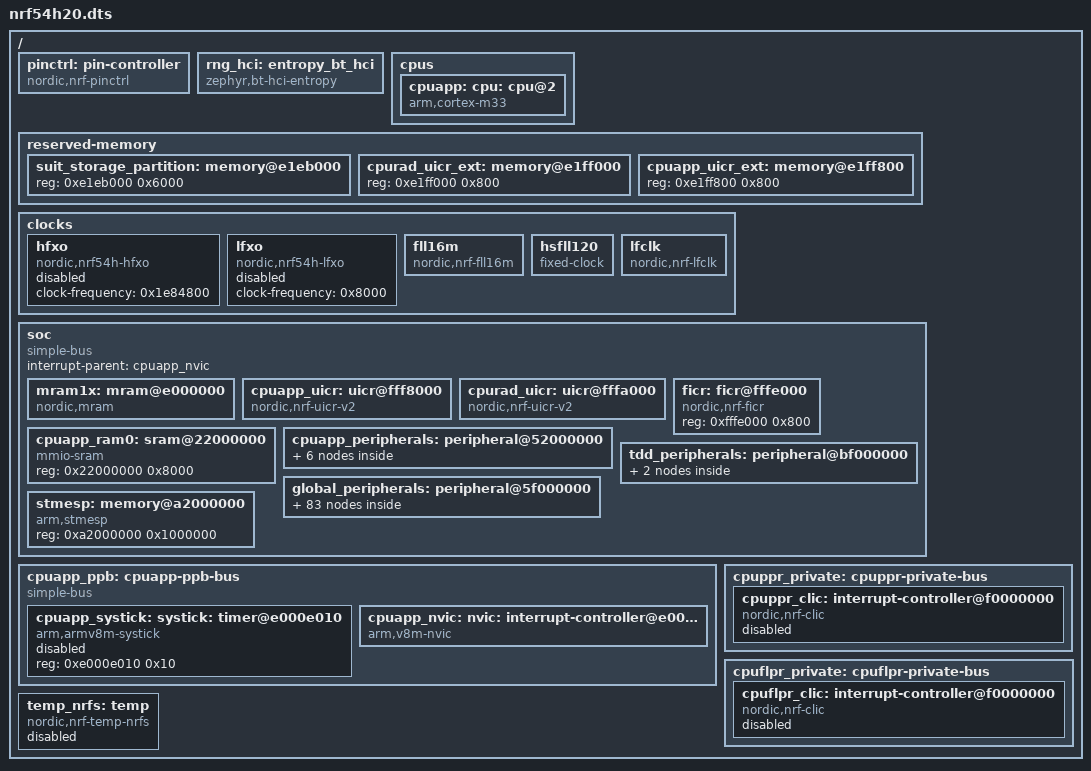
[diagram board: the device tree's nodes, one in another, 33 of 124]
/dts-v1/;

/ {
	#address-cells = < 0x1 >;
	#size-cells = < 0x1 >;
	pinctrl: pin-controller {
		compatible = "nordic,nrf-pinctrl";
	};
	rng_hci: entropy_bt_hci {
		compatible = "zephyr,bt-hci-entropy";
		status = "okay";
	};
	cpus {
		#address-cells = < 0x1 >;
		#size-cells = < 0x0 >;
		cpuapp: cpu: cpu@2 {
			compatible = "arm,cortex-m33";
			reg = < 0x2 >;
			device_type = "cpu";
			clocks = < &cpuapp_hsfll >;
			clock-frequency = < 0x1312d000 >;
		};
	};
	reserved-memory {
		#address-cells = < 0x1 >;
		#size-cells = < 0x1 >;
		suit_storage_partition: memory@e1eb000 {
			reg = < 0xe1eb000 0x6000 >;
		};
		cpurad_uicr_ext: memory@e1ff000 {
			reg = < 0xe1ff000 0x800 >;
			phandle = < 0x7 >;
		};
		cpuapp_uicr_ext: memory@e1ff800 {
			reg = < 0xe1ff800 0x800 >;
			phandle = < 0x6 >;
		};
	};
	clocks {
		hfxo: hfxo {
			compatible = "nordic,nrf54h-hfxo";
			status = "disabled";
			#clock-cells = < 0x0 >;
			clock-frequency = < 0x1e84800 >;
			phandle = < 0x2 >;
		};
		lfxo: lfxo {
			compatible = "nordic,nrf54h-lfxo";
			status = "disabled";
			#clock-cells = < 0x0 >;
			clock-frequency = < 0x8000 >;
			phandle = < 0x3 >;
		};
		fll16m: fll16m {
			compatible = "nordic,nrf-fll16m";
			#clock-cells = < 0x0 >;
			clock-frequency = < 0xf42400 >;
			open-loop-accuracy-ppm = < 0x4e20 >;
			closed-loop-base-accuracy-ppm = < 0x1388 >;
			clocks = < &hfxo >, < &lfxo >;
			clock-names = "hfxo", "lfxo";
			phandle = < 0x4 >;
		};
		hsfll120: hsfll120 {
			compatible = "fixed-clock";
			clocks = < &fll16m >;
			#clock-cells = < 0x0 >;
			clock-frequency = < 0x1312d000 >;
			phandle = < 0xb >;
		};
		lfclk: lfclk {
			compatible = "nordic,nrf-lfclk";
			#clock-cells = < 0x0 >;
			clock-frequency = < 0x8000 >;
			status = "okay";
			lfrc-accuracy-ppm = < 0x1f4 >;
			lflprc-accuracy-ppm = < 0x3e8 >;
			clocks = < &hfxo >, < &lfxo >;
			clock-names = "hfxo", "lfxo";
			phandle = < 0x9 >;
		};
	};
	soc {
		#address-cells = < 0x1 >;
		#size-cells = < 0x1 >;
		compatible = "simple-bus";
		interrupt-parent = < &cpuapp_nvic >;
		ranges;
		mram1x: mram@e000000 {
			compatible = "nordic,mram";
			reg = < 0xe000000 0x200000 >;
			erase-block-size = < 0x1000 >;
			write-block-size = < 0x10 >;
		};
		cpuapp_uicr: uicr@fff8000 {
			compatible = "nordic,nrf-uicr-v2";
			reg = < 0xfff8000 0x800 >;
			domain = < 0x2 >;
			ptr-ext-uicr = < &cpuapp_uicr_ext >;
		};
		cpurad_uicr: uicr@fffa000 {
			compatible = "nordic,nrf-uicr-v2";
			reg = < 0xfffa000 0x800 >;
			domain = < 0x3 >;
			ptr-ext-uicr = < &cpurad_uicr_ext >;
		};
		ficr: ficr@fffe000 {
			compatible = "nordic,nrf-ficr";
			reg = < 0xfffe000 0x800 >;
			#nordic,ficr-cells = < 0x1 >;
			phandle = < 0x8 >;
		};
		cpuapp_ram0: sram@22000000 {
			compatible = "mmio-sram";
			reg = < 0x22000000 0x8000 >;
			#address-cells = < 0x1 >;
			#size-cells = < 0x1 >;
			ranges = < 0x0 0x22000000 0x8000 >;
		};
		cpuapp_peripherals: peripheral@52000000 {
			#address-cells = < 0x1 >;
			#size-cells = < 0x1 >;
			ranges = < 0x0 0x52000000 0x1000000 >;
			cpuapp_hsfll: clock@d000 {
				compatible = "nordic,nrf-hsfll";
				#clock-cells = < 0x0 >;
				reg = < 0xd000 0x1000 >;
				clocks = < &fll16m >;
				clock-frequency = < 0x1312d000 >;
				nordic,ficrs = < &ficr 0x3c8 >, < &ficr 0x3cc >, < &ficr 0x3e4 >;
				nordic,ficr-names = "vsup", "coarse", "fine";
				phandle = < 0x1 >;
			};
			cpuapp_ipct: ipct@13000 {
				compatible = "nordic,nrf-ipct-local";
				reg = < 0x13000 0x1000 >;
				status = "disabled";
				channels = < 0x4 >;
				interrupts = < 0x40 0x1 >, < 0x41 0x1 >;
			};
			cpuapp_wdt010: wdt010: watchdog@14000 {
				compatible = "nordic,nrf-wdt";
				reg = < 0x14000 0x1000 >;
				status = "disabled";
				interrupts = < 0x14 0x1 >;
				clocks = < &lfclk >;
			};
			cpuapp_wdt011: wdt011: watchdog@15000 {
				compatible = "nordic,nrf-wdt";
				reg = < 0x15000 0x1000 >;
				status = "disabled";
				interrupts = < 0x15 0x1 >;
				clocks = < &lfclk >;
			};
			cpuapp_resetinfo: resetinfo@1e000 {
				compatible = "nordic,nrf-resetinfo";
				reg = < 0x1e000 0x1000 >;
			};
			cpuapp_ieee802154: ieee802154 {
				compatible = "nordic,nrf-ieee802154";
				status = "disabled";
			};
		};
		tdd_peripherals: peripheral@bf000000 {
			#address-cells = < 0x1 >;
			#size-cells = < 0x1 >;
			ranges = < 0x0 0xbf000000 0x1000000 >;
			tbm: tbm@3000 {
				compatible = "nordic,nrf-tbm";
				reg = < 0x3000 0x408 >;
				status = "disabled";
				interrupts = < 0x7f 0x1 >;
			};
			tddconf: tddconf@1000 {
				compatible = "nordic,nrf-tddconf";
				reg = < 0x1000 0x10 >;
				status = "disabled";
			};
		};
		global_peripherals: peripheral@5f000000 {
			#address-cells = < 0x1 >;
			#size-cells = < 0x1 >;
			ranges = < 0x0 0x5f000000 0x1000000 >;
			usbhs: usbhs@86000 {
				compatible = "nordic,nrf-usbhs", "snps,dwc2";
				reg = < 0x86000 0x1000 >, < 0x2f700000 0x40000 >;
				reg-names = "wrapper", "core";
				interrupts = < 0x86 0x1 >;
				num-in-eps = < 0x8 >;
				num-out-eps = < 0xa >;
				ghwcfg1 = < 0xaa555000 >;
				ghwcfg2 = < 0x22abfc72 >;
				ghwcfg4 = < 0x1e10aa60 >;
				status = "disabled";
			};
			exmif: spi@95000 {
				compatible = "nordic,nrf-exmif";
				#address-cells = < 0x1 >;
				#size-cells = < 0x0 >;
				reg = < 0x95000 0x500 0x95500 0xb00 >;
				reg-names = "wrapper", "core";
				interrupts = < 0x95 0x1 >;
				clock-frequency = < 0x17d78400 >;
				fifo-depth = < 0x20 >;
				max-xfer-size = < 0x10 >;
				status = "disabled";
			};
			cpusec_bellboard: mailbox@99000 {
				reg = < 0x99000 0x1000 >;
				status = "disabled";
				#mbox-cells = < 0x1 >;
				compatible = "nordic,nrf-bellboard-tx";
			};
			cpuapp_bellboard: mailbox@9a000 {
				reg = < 0x9a000 0x1000 >;
				status = "disabled";
				#mbox-cells = < 0x1 >;
				compatible = "nordic,nrf-bellboard-rx";
			};
			cpurad_bellboard: mailbox@9b000 {
				reg = < 0x9b000 0x1000 >;
				status = "disabled";
				#mbox-cells = < 0x1 >;
				compatible = "nordic,nrf-bellboard-tx";
			};
			canpll: clock-controller@8c2000 {
				compatible = "nordic,nrf-auxpll";
				reg = < 0x8c2000 0x1000 >;
				interrupts = < 0xc2 0x1 >;
				clocks = < &hfxo >;
				#clock-cells = < 0x0 >;
				nordic,ficrs = < &ficr 0x3b8 >;
				nordic,frequency = < 0x0 >;
				nordic,out-div = < 0x2 >;
				nordic,out-drive = < 0x0 >;
				nordic,current-tune = < 0x6 >;
				nordic,sdm-disable;
				nordic,range = "high";
				status = "disabled";
				phandle = < 0xa >;
			};
			cpusys_vevif_tx: cpusys_vevif: mailbox@8c8000 {
				compatible = "nordic,nrf-vevif-task-tx";
				reg = < 0x8c8000 0x1000 >;
				status = "disabled";
				#mbox-cells = < 0x1 >;
				nordic,tasks = < 0x20 >;
				nordic,tasks-mask = < 0xfffff0ff >;
			};
			ipct120: ipct@8d1000 {
				compatible = "nordic,nrf-ipct-global";
				reg = < 0x8d1000 0x1000 >;
				status = "disabled";
				channels = < 0x8 >;
				global-domain-id = < 0xc >;
			};
			cpuflpr_vpr: vpr@8d4000 {
				compatible = "nordic,nrf-vpr-coprocessor";
				reg = < 0x8d4000 0x1000 >;
				status = "disabled";
				#address-cells = < 0x1 >;
				#size-cells = < 0x1 >;
				ranges = < 0x0 0x8d4000 0x1000 >;
				cpuflpr_vevif_tx: cpuflpr_vevif: mailbox@0 {
					compatible = "nordic,nrf-vevif-task-tx";
					reg = < 0x0 0x1000 >;
					status = "disabled";
					#mbox-cells = < 0x1 >;
					nordic,tasks = < 0x20 >;
					nordic,tasks-mask = < 0xffff0000 >;
				};
			};
			can120: can@8d8000 {
				compatible = "nordic,nrf-can";
				reg = < 0x8d8000 0x400 >, < 0x2fbef800 0x800 >, < 0x2fbe8000 0x7800 >;
				reg-names = "wrapper", "m_can", "message_ram";
				interrupts = < 0xd8 0x1 >;
				clocks = < &canpll >;
				bosch,mram-cfg = < 0x0 0x1c 0x8 0x3 0x3 0x0 0x1 0x1 >;
				status = "disabled";
			};
			dppic120: dppic@8e1000 {
				compatible = "nordic,nrf-dppic-global";
				reg = < 0x8e1000 0x1000 >;
				status = "disabled";
			};
			timer120: timer@8e2000 {
				compatible = "nordic,nrf-timer";
				reg = < 0x8e2000 0x1000 >;
				status = "disabled";
				cc-num = < 0x6 >;
				interrupts = < 0xe2 0x1 >;
				max-bit-width = < 0x20 >;
				max-frequency = < 0x1312d000 >;
				prescaler = < 0x0 >;
			};
			timer121: timer@8e3000 {
				compatible = "nordic,nrf-timer";
				reg = < 0x8e3000 0x1000 >;
				status = "disabled";
				cc-num = < 0x6 >;
				interrupts = < 0xe3 0x1 >;
				max-bit-width = < 0x20 >;
				max-frequency = < 0x1312d000 >;
				prescaler = < 0x0 >;
			};
			pwm120: pwm@8e4000 {
				compatible = "nordic,nrf-pwm";
				reg = < 0x8e4000 0x1000 >;
				status = "disabled";
				interrupts = < 0xe4 0x1 >;
				#pwm-cells = < 0x3 >;
			};
			spi120: spi@8e6000 {
				compatible = "nordic,nrf-spim";
				reg = < 0x8e6000 0x1000 >;
				status = "disabled";
				easydma-maxcnt-bits = < 0xf >;
				interrupts = < 0xe6 0x1 >;
				max-frequency = < 0x1e84800 >;
				#address-cells = < 0x1 >;
				#size-cells = < 0x0 >;
				rx-delay-supported;
				rx-delay = < 0x1 >;
				nordic,clockpin-enable = < 0x4 >, < 0x7 >;
			};
			uart120: uart@8e6000 {
				compatible = "nordic,nrf-uarte";
				reg = < 0x8e6000 0x1000 >;
				status = "disabled";
				interrupts = < 0xe6 0x1 >;
				clocks = < &hsfll120 >;
			};
			spi121: spi@8e7000 {
				compatible = "nordic,nrf-spim";
				reg = < 0x8e7000 0x1000 >;
				status = "disabled";
				easydma-maxcnt-bits = < 0xf >;
				interrupts = < 0xe7 0x1 >;
				max-frequency = < 0x1e84800 >;
				#address-cells = < 0x1 >;
				#size-cells = < 0x0 >;
				rx-delay-supported;
				rx-delay = < 0x1 >;
				nordic,clockpin-enable = < 0x4 >, < 0x7 >;
			};
			cpuppr_vpr: vpr@908000 {
				compatible = "nordic,nrf-vpr-coprocessor";
				reg = < 0x908000 0x1000 >;
				status = "disabled";
				#address-cells = < 0x1 >;
				#size-cells = < 0x1 >;
				ranges = < 0x0 0x908000 0x1000 >;
				cpuppr_vevif_tx: cpuppr_vevif: mailbox@0 {
					compatible = "nordic,nrf-vevif-task-tx";
					reg = < 0x0 0x1000 >;
					status = "disabled";
					#mbox-cells = < 0x1 >;
					nordic,tasks = < 0x10 >;
					nordic,tasks-mask = < 0xfffffff0 >;
				};
			};
			ipct130: ipct@921000 {
				compatible = "nordic,nrf-ipct-global";
				reg = < 0x921000 0x1000 >;
				status = "disabled";
				channels = < 0x8 >;
				global-domain-id = < 0xd >;
			};
			dppic130: dppic@922000 {
				compatible = "nordic,nrf-dppic-global";
				reg = < 0x922000 0x1000 >;
				status = "disabled";
			};
			rtc130: rtc@928000 {
				compatible = "nordic,nrf-rtc";
				reg = < 0x928000 0x1000 >;
				status = "disabled";
				cc-num = < 0x4 >;
				clock-frequency = < 0x8000 >;
				interrupts = < 0x128 0x1 >;
				clocks = < &lfclk >;
				prescaler = < 0x1 >;
			};
			rtc131: rtc@929000 {
				compatible = "nordic,nrf-rtc";
				reg = < 0x929000 0x1000 >;
				status = "disabled";
				cc-num = < 0x4 >;
				clock-frequency = < 0x8000 >;
				interrupts = < 0x129 0x1 >;
				clocks = < &lfclk >;
				prescaler = < 0x1 >;
			};
			wdt131: watchdog@92b000 {
				compatible = "nordic,nrf-wdt";
				reg = < 0x92b000 0x1000 >;
				status = "disabled";
				interrupts = < 0x12b 0x1 >;
				clocks = < &lfclk >;
			};
			wdt132: watchdog@92c000 {
				compatible = "nordic,nrf-wdt";
				reg = < 0x92c000 0x1000 >;
				status = "disabled";
				interrupts = < 0x12c 0x1 >;
				clocks = < &lfclk >;
			};
			egu130: egu@92d000 {
				compatible = "nordic,nrf-egu";
				reg = < 0x92d000 0x1000 >;
				status = "disabled";
				interrupts = < 0x12d 0x1 >;
			};
			gpiote130: gpiote@934000 {
				compatible = "nordic,nrf-gpiote";
				reg = < 0x934000 0x1000 >;
				status = "disabled";
				instance = < 0x82 >;
				interrupts = < 0x69 0x1 >;
				phandle = < 0xc >;
			};
			gpio0: gpio@938000 {
				compatible = "nordic,nrf-gpio";
				reg = < 0x938000 0x200 >;
				status = "disabled";
				#gpio-cells = < 0x2 >;
				gpio-controller;
				gpiote-instance = < &gpiote130 >;
				ngpios = < 0xc >;
				port = < 0x0 >;
			};
			gpio1: gpio@938200 {
				compatible = "nordic,nrf-gpio";
				reg = < 0x938200 0x200 >;
				status = "disabled";
				#gpio-cells = < 0x2 >;
				gpio-controller;
				gpiote-instance = < &gpiote130 >;
				ngpios = < 0xc >;
				port = < 0x1 >;
			};
			gpio2: gpio@938400 {
				compatible = "nordic,nrf-gpio";
				reg = < 0x938400 0x200 >;
				status = "disabled";
				#gpio-cells = < 0x2 >;
				gpio-controller;
				gpiote-instance = < &gpiote130 >;
				ngpios = < 0xc >;
				port = < 0x2 >;
			};
			gpio6: gpio@938c00 {
				compatible = "nordic,nrf-gpio";
				reg = < 0x938c00 0x200 >;
				status = "disabled";
				#gpio-cells = < 0x2 >;
				gpio-controller;
				ngpios = < 0xe >;
				port = < 0x6 >;
			};
			gpio7: gpio@938e00 {
				compatible = "nordic,nrf-gpio";
				reg = < 0x938e00 0x200 >;
				status = "disabled";
				#gpio-cells = < 0x2 >;
				gpio-controller;
				ngpios = < 0x8 >;
				port = < 0x7 >;
			};
			gpio9: gpio@939200 {
				compatible = "nordic,nrf-gpio";
				reg = < 0x939200 0x200 >;
				status = "disabled";
				#gpio-cells = < 0x2 >;
				gpio-controller;
				gpiote-instance = < &gpiote130 >;
				ngpios = < 0x6 >;
				port = < 0x9 >;
			};
			dppic131: dppic@981000 {
				compatible = "nordic,nrf-dppic-global";
				reg = < 0x981000 0x1000 >;
				status = "disabled";
			};
			adc: adc@982000 {
				compatible = "nordic,nrf-saadc";
				reg = < 0x982000 0x1000 >;
				interrupts = < 0x182 0x1 >;
				status = "disabled";
				#io-channel-cells = < 0x1 >;
			};
			comp: comparator@983000 {
				compatible = "nordic,nrf-comp";
				reg = < 0x983000 0x1000 >;
				status = "disabled";
				interrupts = < 0x183 0x1 >;
				#io-channel-cells = < 0x1 >;
			};
			temp: temperature-sensor@984000 {
				compatible = "nordic,nrf-temp";
				reg = < 0x984000 0x1000 >;
				interrupts = < 0x184 0x1 >;
				status = "disabled";
			};
			nfct: nfct@985000 {
				compatible = "nordic,nrf-nfct";
				reg = < 0x985000 0x1000 >;
				status = "disabled";
				interrupts = < 0x185 0x1 >;
			};
			dppic132: dppic@991000 {
				compatible = "nordic,nrf-dppic-global";
				reg = < 0x991000 0x1000 >;
				status = "disabled";
			};
			qdec130: qdec@994000 {
				compatible = "nordic,nrf-qdec";
				reg = < 0x994000 0x1000 >;
				status = "disabled";
				interrupts = < 0x194 0x1 >;
			};
			qdec131: qdec@995000 {
				compatible = "nordic,nrf-qdec";
				reg = < 0x995000 0x1000 >;
				status = "disabled";
				interrupts = < 0x195 0x1 >;
			};
			grtc: grtc@99c000 {
				compatible = "nordic,nrf-grtc";
				reg = < 0x99c000 0x1000 >;
				status = "disabled";
				cc-num = < 0x10 >;
				clocks = < &lfclk >;
				interrupts = < 0x6d 0x1 >;
			};
			dppic133: dppic@9a1000 {
				compatible = "nordic,nrf-dppic-global";
				reg = < 0x9a1000 0x1000 >;
				status = "disabled";
			};
			timer130: timer@9a2000 {
				compatible = "nordic,nrf-timer";
				reg = < 0x9a2000 0x1000 >;
				status = "disabled";
				cc-num = < 0x6 >;
				interrupts = < 0x1a2 0x1 >;
				clocks = < &fll16m >;
				max-bit-width = < 0x20 >;
				prescaler = < 0x0 >;
			};
			timer131: timer@9a3000 {
				compatible = "nordic,nrf-timer";
				reg = < 0x9a3000 0x1000 >;
				status = "disabled";
				cc-num = < 0x6 >;
				interrupts = < 0x1a3 0x1 >;
				clocks = < &fll16m >;
				max-bit-width = < 0x20 >;
				prescaler = < 0x0 >;
			};
			pwm130: pwm@9a4000 {
				compatible = "nordic,nrf-pwm";
				reg = < 0x9a4000 0x1000 >;
				status = "disabled";
				interrupts = < 0x1a4 0x1 >;
				clocks = < &fll16m >;
				#pwm-cells = < 0x3 >;
			};
			i2c130: i2c@9a5000 {
				compatible = "nordic,nrf-twim";
				reg = < 0x9a5000 0x1000 >;
				status = "disabled";
				interrupts = < 0x1a5 0x1 >;
				clocks = < &fll16m >;
				easydma-maxcnt-bits = < 0xf >;
				#address-cells = < 0x1 >;
				#size-cells = < 0x0 >;
				nordic,clockpin-enable = < 0xc >, < 0xb >;
			};
			spi130: spi@9a5000 {
				compatible = "nordic,nrf-spim";
				reg = < 0x9a5000 0x1000 >;
				status = "disabled";
				easydma-maxcnt-bits = < 0xf >;
				interrupts = < 0x1a5 0x1 >;
				clocks = < &fll16m >;
				max-frequency = < 0x7a1200 >;
				#address-cells = < 0x1 >;
				#size-cells = < 0x0 >;
				rx-delay-supported;
				rx-delay = < 0x1 >;
				nordic,clockpin-enable = < 0x5 >, < 0x4 >, < 0x9 >, < 0x7 >;
			};
			uart130: uart@9a5000 {
				compatible = "nordic,nrf-uarte";
				reg = < 0x9a5000 0x1000 >;
				status = "disabled";
				interrupts = < 0x1a5 0x1 >;
				clocks = < &fll16m >;
				nordic,clockpin-enable = < 0x0 >;
			};
			i2c131: i2c@9a6000 {
				compatible = "nordic,nrf-twim";
				reg = < 0x9a6000 0x1000 >;
				status = "disabled";
				interrupts = < 0x1a6 0x1 >;
				clocks = < &fll16m >;
				easydma-maxcnt-bits = < 0xf >;
				#address-cells = < 0x1 >;
				#size-cells = < 0x0 >;
				nordic,clockpin-enable = < 0xc >, < 0xb >;
			};
			spi131: spi@9a6000 {
				compatible = "nordic,nrf-spim";
				reg = < 0x9a6000 0x1000 >;
				status = "disabled";
				easydma-maxcnt-bits = < 0xf >;
				interrupts = < 0x1a6 0x1 >;
				clocks = < &fll16m >;
				max-frequency = < 0x7a1200 >;
				#address-cells = < 0x1 >;
				#size-cells = < 0x0 >;
				rx-delay-supported;
				rx-delay = < 0x1 >;
				nordic,clockpin-enable = < 0x5 >, < 0x4 >, < 0x9 >, < 0x7 >;
			};
			uart131: uart@9a6000 {
				compatible = "nordic,nrf-uarte";
				reg = < 0x9a6000 0x1000 >;
				status = "disabled";
				interrupts = < 0x1a6 0x1 >;
				clocks = < &fll16m >;
				nordic,clockpin-enable = < 0x0 >;
			};
			dppic134: dppic@9b1000 {
				compatible = "nordic,nrf-dppic-global";
				reg = < 0x9b1000 0x1000 >;
				status = "disabled";
			};
			timer132: timer@9b2000 {
				compatible = "nordic,nrf-timer";
				reg = < 0x9b2000 0x1000 >;
				status = "disabled";
				cc-num = < 0x6 >;
				interrupts = < 0x1b2 0x1 >;
				clocks = < &fll16m >;
				max-bit-width = < 0x20 >;
				prescaler = < 0x0 >;
			};
			timer133: timer@9b3000 {
				compatible = "nordic,nrf-timer";
				reg = < 0x9b3000 0x1000 >;
				status = "disabled";
				cc-num = < 0x6 >;
				interrupts = < 0x1b3 0x1 >;
				clocks = < &fll16m >;
				max-bit-width = < 0x20 >;
				prescaler = < 0x0 >;
			};
			pwm131: pwm@9b4000 {
				compatible = "nordic,nrf-pwm";
				reg = < 0x9b4000 0x1000 >;
				status = "disabled";
				interrupts = < 0x1b4 0x1 >;
				clocks = < &fll16m >;
				#pwm-cells = < 0x3 >;
			};
			i2c132: i2c@9b5000 {
				compatible = "nordic,nrf-twim";
				reg = < 0x9b5000 0x1000 >;
				status = "disabled";
				interrupts = < 0x1b5 0x1 >;
				clocks = < &fll16m >;
				easydma-maxcnt-bits = < 0xf >;
				#address-cells = < 0x1 >;
				#size-cells = < 0x0 >;
				nordic,clockpin-enable = < 0xc >, < 0xb >;
			};
			spi132: spi@9b5000 {
				compatible = "nordic,nrf-spim";
				reg = < 0x9b5000 0x1000 >;
				status = "disabled";
				easydma-maxcnt-bits = < 0xf >;
				interrupts = < 0x1b5 0x1 >;
				clocks = < &fll16m >;
				max-frequency = < 0x7a1200 >;
				#address-cells = < 0x1 >;
				#size-cells = < 0x0 >;
				rx-delay-supported;
				rx-delay = < 0x1 >;
				nordic,clockpin-enable = < 0x5 >, < 0x4 >, < 0x9 >, < 0x7 >;
			};
			uart132: uart@9b5000 {
				compatible = "nordic,nrf-uarte";
				reg = < 0x9b5000 0x1000 >;
				status = "disabled";
				interrupts = < 0x1b5 0x1 >;
				clocks = < &fll16m >;
				nordic,clockpin-enable = < 0x0 >;
			};
			i2c133: i2c@9b6000 {
				compatible = "nordic,nrf-twim";
				reg = < 0x9b6000 0x1000 >;
				status = "disabled";
				interrupts = < 0x1b6 0x1 >;
				clocks = < &fll16m >;
				easydma-maxcnt-bits = < 0xf >;
				#address-cells = < 0x1 >;
				#size-cells = < 0x0 >;
				nordic,clockpin-enable = < 0xc >, < 0xb >;
			};
			spi133: spi@9b6000 {
				compatible = "nordic,nrf-spim";
				reg = < 0x9b6000 0x1000 >;
				status = "disabled";
				easydma-maxcnt-bits = < 0xf >;
				interrupts = < 0x1b6 0x1 >;
				clocks = < &fll16m >;
				max-frequency = < 0x7a1200 >;
				#address-cells = < 0x1 >;
				#size-cells = < 0x0 >;
				rx-delay-supported;
				rx-delay = < 0x1 >;
				nordic,clockpin-enable = < 0x5 >, < 0x4 >, < 0x9 >, < 0x7 >;
			};
			uart133: uart@9b6000 {
				compatible = "nordic,nrf-uarte";
				reg = < 0x9b6000 0x1000 >;
				status = "disabled";
				interrupts = < 0x1b6 0x1 >;
				clocks = < &fll16m >;
				nordic,clockpin-enable = < 0x0 >;
			};
			dppic135: dppic@9c1000 {
				compatible = "nordic,nrf-dppic-global";
				reg = < 0x9c1000 0x1000 >;
				status = "disabled";
			};
			timer134: timer@9c2000 {
				compatible = "nordic,nrf-timer";
				reg = < 0x9c2000 0x1000 >;
				status = "disabled";
				cc-num = < 0x6 >;
				interrupts = < 0x1c2 0x1 >;
				clocks = < &fll16m >;
				max-bit-width = < 0x20 >;
				prescaler = < 0x0 >;
			};
			timer135: timer@9c3000 {
				compatible = "nordic,nrf-timer";
				reg = < 0x9c3000 0x1000 >;
				status = "disabled";
				cc-num = < 0x6 >;
				interrupts = < 0x1c3 0x1 >;
				clocks = < &fll16m >;
				max-bit-width = < 0x20 >;
				prescaler = < 0x0 >;
			};
			pwm132: pwm@9c4000 {
				compatible = "nordic,nrf-pwm";
				reg = < 0x9c4000 0x1000 >;
				status = "disabled";
				interrupts = < 0x1c4 0x1 >;
				clocks = < &fll16m >;
				#pwm-cells = < 0x3 >;
			};
			i2c134: i2c@9c5000 {
				compatible = "nordic,nrf-twim";
				reg = < 0x9c5000 0x1000 >;
				status = "disabled";
				interrupts = < 0x1c5 0x1 >;
				clocks = < &fll16m >;
				easydma-maxcnt-bits = < 0xf >;
				#address-cells = < 0x1 >;
				#size-cells = < 0x0 >;
				nordic,clockpin-enable = < 0xc >, < 0xb >;
			};
			spi134: spi@9c5000 {
				compatible = "nordic,nrf-spim";
				reg = < 0x9c5000 0x1000 >;
				status = "disabled";
				easydma-maxcnt-bits = < 0xf >;
				interrupts = < 0x1c5 0x1 >;
				clocks = < &fll16m >;
				max-frequency = < 0x7a1200 >;
				#address-cells = < 0x1 >;
				#size-cells = < 0x0 >;
				rx-delay-supported;
				rx-delay = < 0x1 >;
				nordic,clockpin-enable = < 0x5 >, < 0x4 >, < 0x9 >, < 0x7 >;
			};
			uart134: uart@9c5000 {
				compatible = "nordic,nrf-uarte";
				reg = < 0x9c5000 0x1000 >;
				status = "disabled";
				interrupts = < 0x1c5 0x1 >;
				clocks = < &fll16m >;
				nordic,clockpin-enable = < 0x0 >;
			};
			i2c135: i2c@9c6000 {
				compatible = "nordic,nrf-twim";
				reg = < 0x9c6000 0x1000 >;
				status = "disabled";
				interrupts = < 0x1c6 0x1 >;
				clocks = < &fll16m >;
				easydma-maxcnt-bits = < 0xf >;
				#address-cells = < 0x1 >;
				#size-cells = < 0x0 >;
				nordic,clockpin-enable = < 0xc >, < 0xb >;
			};
			spi135: spi@9c6000 {
				compatible = "nordic,nrf-spim";
				reg = < 0x9c6000 0x1000 >;
				status = "disabled";
				easydma-maxcnt-bits = < 0xf >;
				interrupts = < 0x1c6 0x1 >;
				clocks = < &fll16m >;
				max-frequency = < 0x7a1200 >;
				#address-cells = < 0x1 >;
				#size-cells = < 0x0 >;
				rx-delay-supported;
				rx-delay = < 0x1 >;
				nordic,clockpin-enable = < 0x5 >, < 0x4 >, < 0x9 >, < 0x7 >;
			};
			uart135: uart@9c6000 {
				compatible = "nordic,nrf-uarte";
				reg = < 0x9c6000 0x1000 >;
				status = "disabled";
				interrupts = < 0x1c6 0x1 >;
				clocks = < &fll16m >;
				nordic,clockpin-enable = < 0x0 >;
			};
			dppic136: dppic@9d1000 {
				compatible = "nordic,nrf-dppic-global";
				reg = < 0x9d1000 0x1000 >;
				status = "disabled";
			};
			timer136: timer@9d2000 {
				compatible = "nordic,nrf-timer";
				reg = < 0x9d2000 0x1000 >;
				status = "disabled";
				cc-num = < 0x6 >;
				interrupts = < 0x1d2 0x1 >;
				clocks = < &fll16m >;
				max-bit-width = < 0x20 >;
				prescaler = < 0x0 >;
			};
			timer137: timer@9d3000 {
				compatible = "nordic,nrf-timer";
				reg = < 0x9d3000 0x1000 >;
				status = "disabled";
				cc-num = < 0x6 >;
				interrupts = < 0x1d3 0x1 >;
				clocks = < &fll16m >;
				max-bit-width = < 0x20 >;
				prescaler = < 0x0 >;
			};
			pwm133: pwm@9d4000 {
				compatible = "nordic,nrf-pwm";
				reg = < 0x9d4000 0x1000 >;
				status = "disabled";
				interrupts = < 0x1d4 0x1 >;
				clocks = < &fll16m >;
				#pwm-cells = < 0x3 >;
			};
			i2c136: i2c@9d5000 {
				compatible = "nordic,nrf-twim";
				reg = < 0x9d5000 0x1000 >;
				status = "disabled";
				interrupts = < 0x1d5 0x1 >;
				clocks = < &fll16m >;
				easydma-maxcnt-bits = < 0xf >;
				#address-cells = < 0x1 >;
				#size-cells = < 0x0 >;
				nordic,clockpin-enable = < 0xc >, < 0xb >;
			};
			spi136: spi@9d5000 {
				compatible = "nordic,nrf-spim";
				reg = < 0x9d5000 0x1000 >;
				status = "disabled";
				easydma-maxcnt-bits = < 0xf >;
				interrupts = < 0x1d5 0x1 >;
				clocks = < &fll16m >;
				max-frequency = < 0x7a1200 >;
				#address-cells = < 0x1 >;
				#size-cells = < 0x0 >;
				rx-delay-supported;
				rx-delay = < 0x1 >;
				nordic,clockpin-enable = < 0x5 >, < 0x4 >, < 0x9 >, < 0x7 >;
			};
			uart136: uart@9d5000 {
				compatible = "nordic,nrf-uarte";
				reg = < 0x9d5000 0x1000 >;
				status = "disabled";
				interrupts = < 0x1d5 0x1 >;
				clocks = < &fll16m >;
				nordic,clockpin-enable = < 0x0 >;
			};
			i2c137: i2c@9d6000 {
				compatible = "nordic,nrf-twim";
				reg = < 0x9d6000 0x1000 >;
				status = "disabled";
				interrupts = < 0x1d6 0x1 >;
				clocks = < &fll16m >;
				easydma-maxcnt-bits = < 0xf >;
				#address-cells = < 0x1 >;
				#size-cells = < 0x0 >;
				nordic,clockpin-enable = < 0xc >, < 0xb >;
			};
			spi137: spi@9d6000 {
				compatible = "nordic,nrf-spim";
				reg = < 0x9d6000 0x1000 >;
				status = "disabled";
				easydma-maxcnt-bits = < 0xf >;
				interrupts = < 0x1d6 0x1 >;
				clocks = < &fll16m >;
				max-frequency = < 0x7a1200 >;
				#address-cells = < 0x1 >;
				#size-cells = < 0x0 >;
				rx-delay-supported;
				rx-delay = < 0x1 >;
				nordic,clockpin-enable = < 0x5 >, < 0x4 >, < 0x9 >, < 0x7 >;
			};
			uart137: uart@9d6000 {
				compatible = "nordic,nrf-uarte";
				reg = < 0x9d6000 0x1000 >;
				status = "disabled";
				interrupts = < 0x1d6 0x1 >;
				clocks = < &fll16m >;
				nordic,clockpin-enable = < 0x0 >;
			};
		};
		stmesp: memory@a2000000 {
			compatible = "arm,stmesp";
			reg = < 0xa2000000 0x1000000 >;
		};
	};
	cpuapp_ppb: cpuapp-ppb-bus {
		#address-cells = < 0x1 >;
		#size-cells = < 0x1 >;
		compatible = "simple-bus";
		ranges;
		cpuapp_systick: systick: timer@e000e010 {
			compatible = "arm,armv8m-systick";
			reg = < 0xe000e010 0x10 >;
			status = "disabled";
		};
		cpuapp_nvic: nvic: interrupt-controller@e000e100 {
			compatible = "arm,v8m-nvic";
			reg = < 0xe000e100 0xc00 >;
			arm,num-irq-priority-bits = < 0x3 >;
			#interrupt-cells = < 0x2 >;
			interrupt-controller;
			#address-cells = < 0x1 >;
			phandle = < 0x5 >;
		};
	};
	cpuppr_private: cpuppr-private-bus {
		#address-cells = < 0x1 >;
		#size-cells = < 0x1 >;
		cpuppr_clic: interrupt-controller@f0000000 {
			compatible = "nordic,nrf-clic";
			reg = < 0xf0000000 0x3000 >;
			status = "disabled";
			#interrupt-cells = < 0x2 >;
			interrupt-controller;
			#address-cells = < 0x1 >;
		};
	};
	cpuflpr_private: cpuflpr-private-bus {
		#address-cells = < 0x1 >;
		#size-cells = < 0x1 >;
		cpuflpr_clic: interrupt-controller@f0000000 {
			compatible = "nordic,nrf-clic";
			reg = < 0xf0000000 0x3000 >;
			status = "disabled";
			#interrupt-cells = < 0x2 >;
			interrupt-controller;
			#address-cells = < 0x1 >;
		};
	};
	temp_nrfs: temp {
		compatible = "nordic,nrf-temp-nrfs";
		status = "disabled";
	};
};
